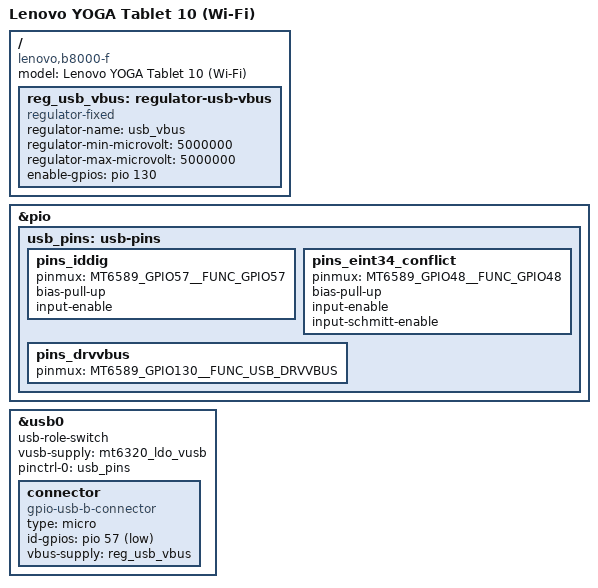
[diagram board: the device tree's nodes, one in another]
// SPDX-License-Identifier: (GPL-2.0-only OR BSD-2-Clause)
/*
 * Copyright (c) 2026 Akari Tsuyukusa <akkun11.open@gmail.com>
 */

#include <dt-bindings/gpio/gpio.h>
#include <dt-bindings/pinctrl/mt6589-pinfunc.h>
#include "mt6589-lenovo-b8000.dtsi"

/ {
	model = "Lenovo YOGA Tablet 10 (Wi-Fi)";
	compatible = "lenovo,b8000-f", "mediatek,mt6589";

	reg_usb_vbus: regulator-usb-vbus {
		compatible = "regulator-fixed";
		regulator-name = "usb_vbus";
		regulator-min-microvolt = <5000000>;
		regulator-max-microvolt = <5000000>;
		enable-gpios = <&pio 130 GPIO_ACTIVE_HIGH>;
	};
};

&pio {
	usb_pins: usb-pins {
		pins_iddig {
			pinmux = <MT6589_GPIO57__FUNC_GPIO57>;
			bias-pull-up;
			input-enable;
		};

		pins_eint34_conflict {
			pinmux = <MT6589_GPIO48__FUNC_GPIO48>;
			bias-pull-up;
			input-enable;
			input-schmitt-enable;
		};


		pins_drvvbus {
			pinmux = <MT6589_GPIO130__FUNC_USB_DRVVBUS>;
		};
	};
};

&usb0 {
	status = "okay";
	usb-role-switch;
	vusb-supply = <&mt6320_ldo_vusb>;
	pinctrl-names = "default";
	pinctrl-0 = <&usb_pins>;

	connector {
		compatible = "gpio-usb-b-connector", "usb-b-connector";
		type = "micro";
		id-gpios = <&pio 57 GPIO_ACTIVE_LOW>;
		vbus-supply = <&reg_usb_vbus>;
	};
};
